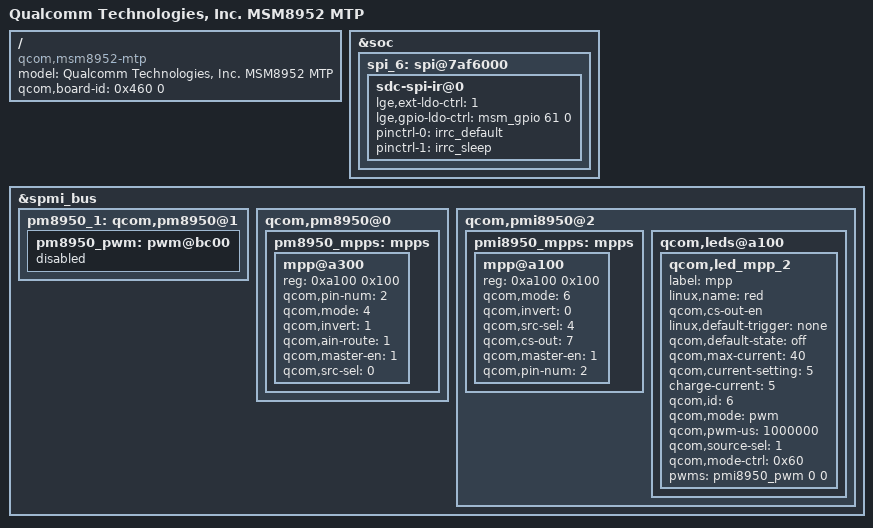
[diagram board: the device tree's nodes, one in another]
/*
 * Copyright (c) 2015, The Linux Foundation. All rights reserved.
 *
 * This program is free software; you can redistribute it and/or modify
 * it under the terms of the GNU General Public License version 2 and
 * only version 2 as published by the Free Software Foundation.
 *
 * This program is distributed in the hope that it will be useful,
 * but WITHOUT ANY WARRANTY; without even the implied warranty of
 * MERCHANTABILITY or FITNESS FOR A PARTICULAR PURPOSE.  See the
 * GNU General Public License for more details.
 */

/dts-v1/;

#include "msm8952-p1v_att_us.dtsi"

/ {
	model = "Qualcomm Technologies, Inc. MSM8952 MTP";
	compatible = "qcom,msm8952-mtp", "qcom,msm8952", "qcom,mtp", "lge,msm8952-p1v_att_us";
	qcom,board-id= <0x460 0>; /* rev_b */
};

&soc {
	spi_6: spi@7af6000 {
		sdc-spi-ir@0 {
			lge,ext-ldo-ctrl = <1>;
			lge,gpio-ldo-ctrl = <&msm_gpio 61 0>;
			pinctrl-names = "irrc_default", "irrc_sleep";
			pinctrl-0 = <&irrc_default>;
			pinctrl-1 = <&irrc_sleep>;
		};
	};
};

&spmi_bus {

		pm8950_1: qcom,pm8950@1 {
			pm8950_pwm: pwm@bc00 {
				status = "disabled";
			};
		};

		qcom,pm8950@0 {
			pm8950_mpps: mpps {
				mpp@a300 {
					/* MPP2 - PA_THERM config */
					reg = <0xa100 0x100>;
					qcom,pin-num = <2>;
					qcom,mode = <4>; /* AIN input */
					qcom,invert = <1>; /* Enable MPP */
					qcom,ain-route = <1>; /* AMUX 6 */
					qcom,master-en = <1>;
					qcom,src-sel = <0>; /* Function constant */
				};
			};
		};

		qcom,pmi8950@2 {
			pmi8950_mpps: mpps {
				mpp@a100 {
					reg = <0xa100 0x100>;
					qcom,mode = <6>;
					qcom,invert = <0>;
					qcom,src-sel = <4>;
					qcom,cs-out = <7>;
					qcom,master-en = <1>;
					qcom,pin-num = <2>;
				};
			};
			qcom,leds@a100 {
				status = "okay";
				qcom,led_mpp_2 {
					label = "mpp";
					linux,name = "red";
					qcom,cs-out-en;
					linux,default-trigger = "none";
					qcom,default-state = "off";
					qcom,max-current = <40>;
					qcom,current-setting = <5>;
					charge-current = <5>;
					qcom,id = <6>;
					qcom,mode = "pwm";
					qcom,pwm-us = <1000000>;
					qcom,source-sel = <1>;
					qcom,mode-ctrl = <0x60>;
					pwms = <&pmi8950_pwm 0 0>;

				};
			};
		};
	};
